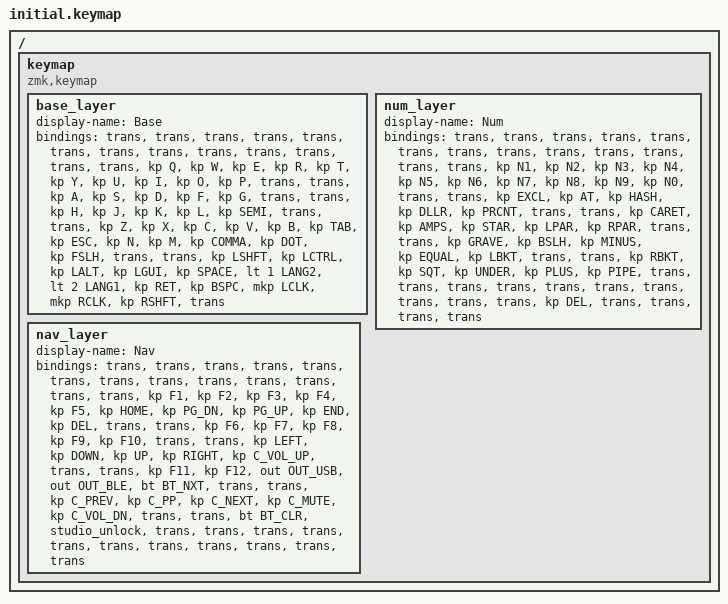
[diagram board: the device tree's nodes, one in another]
#include <behaviors.dtsi>
#include <dt-bindings/zmk/bt.h>
#include <dt-bindings/zmk/keys.h>
#include <dt-bindings/zmk/outputs.h>
#include <dt-bindings/zmk/pointing.h>

/ {
    keymap {
        compatible = "zmk,keymap";
        base_layer {
            display-name = "Base";
            bindings = <
&trans  &trans  &trans  &trans  &trans  &trans  &trans  &trans  &trans  &trans  &trans  &trans  &trans  &kp Q  &kp W  &kp E  &kp R  &kp T  &kp Y  &kp U  &kp I  &kp O  &kp P  &trans  &trans  &kp A  &kp S  &kp D  &kp F  &kp G  &trans  &trans  &kp H  &kp J  &kp K  &kp L  &kp SEMI  &trans  &trans  &kp Z  &kp X  &kp C  &kp V  &kp B  &kp TAB  &kp ESC  &kp N  &kp M  &kp COMMA  &kp DOT  &kp FSLH  &trans  &trans  &kp LSHFT  &kp LCTRL  &kp LALT  &kp LGUI  &kp SPACE  &lt 1 LANG2  &lt 2 LANG1  &kp RET  &kp BSPC  &mkp LCLK  &mkp RCLK  &kp RSHFT  &trans
            >;
        };
        num_layer {
            display-name = "Num";
            bindings = <
&trans  &trans  &trans  &trans  &trans  &trans  &trans  &trans  &trans  &trans  &trans  &trans  &trans  &kp N1  &kp N2  &kp N3  &kp N4  &kp N5  &kp N6  &kp N7  &kp N8  &kp N9  &kp N0  &trans  &trans  &kp EXCL  &kp AT  &kp HASH  &kp DLLR  &kp PRCNT  &trans  &trans  &kp CARET  &kp AMPS  &kp STAR  &kp LPAR  &kp RPAR  &trans  &trans  &kp GRAVE  &kp BSLH  &kp MINUS  &kp EQUAL  &kp LBKT  &trans  &trans  &kp RBKT  &kp SQT  &kp UNDER  &kp PLUS  &kp PIPE  &trans  &trans  &trans  &trans  &trans  &trans  &trans  &trans  &trans  &trans  &kp DEL  &trans  &trans  &trans  &trans
            >;
        };
        nav_layer {
            display-name = "Nav";
            bindings = <
&trans  &trans  &trans  &trans  &trans  &trans  &trans  &trans  &trans  &trans  &trans  &trans  &trans  &kp F1  &kp F2  &kp F3  &kp F4  &kp F5  &kp HOME  &kp PG_DN  &kp PG_UP  &kp END  &kp DEL  &trans  &trans  &kp F6  &kp F7  &kp F8  &kp F9  &kp F10  &trans  &trans  &kp LEFT  &kp DOWN  &kp UP  &kp RIGHT  &kp C_VOL_UP  &trans  &trans  &kp F11  &kp F12  &out OUT_USB  &out OUT_BLE  &bt BT_NXT  &trans  &trans  &kp C_PREV  &kp C_PP  &kp C_NEXT  &kp C_MUTE  &kp C_VOL_DN  &trans  &trans  &bt BT_CLR  &studio_unlock  &trans  &trans  &trans  &trans  &trans  &trans  &trans  &trans  &trans  &trans  &trans
            >;
        };
    };
};
